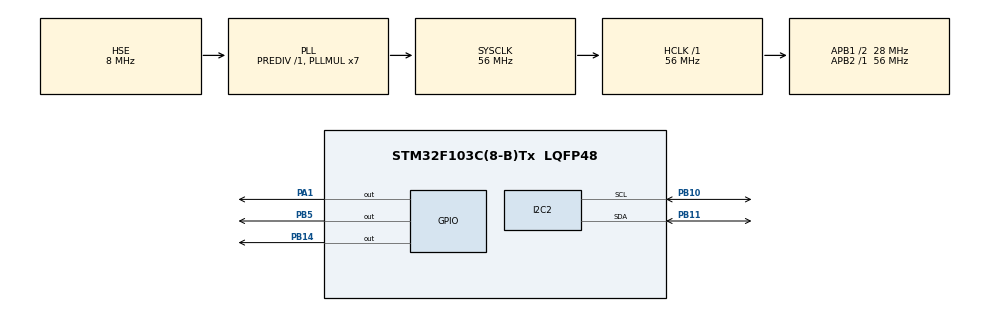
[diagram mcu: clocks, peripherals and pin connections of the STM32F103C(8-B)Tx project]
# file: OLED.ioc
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Mcu.Family=STM32F1
Mcu.Name=STM32F103C(8-B)Tx
Mcu.Package=LQFP48
NVIC.PriorityGroup=NVIC_PRIORITYGROUP_4
PA1.GPIO_PuPd=GPIO_PULLUP
PA1.GPIO_Speed=GPIO_SPEED_FREQ_HIGH
PA1.PinState=GPIO_PIN_SET
PA1.Signal=GPIO_Output
PA13.Mode=Serial_Wire
PA13.Signal=SYS_JTMS-SWDIO
PA14.Mode=Serial_Wire
PA14.Signal=SYS_JTCK-SWCLK
PB10.Mode=I2C
PB10.Signal=I2C2_SCL
PB11.Mode=I2C
PB11.Signal=I2C2_SDA
PB14.GPIO_PuPd=GPIO_PULLUP
PB14.GPIO_Speed=GPIO_SPEED_FREQ_HIGH
PB14.PinState=GPIO_PIN_SET
PB14.Signal=GPIO_Output
PB5.GPIO_PuPd=GPIO_PULLUP
PB5.GPIO_Speed=GPIO_SPEED_FREQ_HIGH
PB5.PinState=GPIO_PIN_SET
PB5.Signal=GPIO_Output
PD0-OSC_IN.Mode=HSE-External-Oscillator
PD0-OSC_IN.Signal=RCC_OSC_IN
PD1-OSC_OUT.Mode=HSE-External-Oscillator
PD1-OSC_OUT.Signal=RCC_OSC_OUT
ProjectManager.HeapSize=0x200
ProjectManager.StackSize=0x400
ProjectManager.TargetToolchain=MDK-ARM V5.27
RCC.AHBFreq_Value=56000000
RCC.APB1CLKDivider=RCC_HCLK_DIV2
RCC.APB1Freq_Value=28000000
RCC.APB1TimFreq_Value=56000000
RCC.APB2Freq_Value=56000000
RCC.APB2TimFreq_Value=56000000
RCC.HCLKFreq_Value=56000000
RCC.PLLMUL=RCC_PLL_MUL7
RCC.PLLSourceVirtual=RCC_PLLSOURCE_HSE
RCC.SYSCLKFreq_VALUE=56000000
RCC.SYSCLKSource=RCC_SYSCLKSOURCE_PLLCLK
RCC.USBFreq_Value=56000000
board=custom

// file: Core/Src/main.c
/* USER CODE BEGIN Header */
/**
  ******************************************************************************
  * @file           : main.c
  * @brief          : Main program body
  ******************************************************************************
  * @attention
  *
  * <h2><center>&copy; Copyright (c) 2022 STMicroelectronics.
  * All rights reserved.</center></h2>
  *
  * This software component is licensed by ST under BSD 3-Clause license,
  * the "License"; You may not use this file except in compliance with the
  * License. You may obtain a copy of the License at:
  *                        opensource.org/licenses/BSD-3-Clause
  *
  ******************************************************************************
  */
/* USER CODE END Header */
#include "main.h"
#include "i2c.h"
#include "gpio.h"

/* USER CODE BEGIN Includes */

//void power_pin_init(void)
//{
//	GPIO_InitTypeDef  GPIO_InitStructure;
//	RCC_APB2PeriphClockCmd(RCC_APB2Periph_GPIOB, ENABLE);
//	GPIO_InitStructure.GPIO_Pin = GPIO_Pin_12;//	 PB12 POWER控制端口
// 	GPIO_InitStructure.GPIO_Mode =GPIO_Mode_Out_PP; 		 //推挽输出
//	GPIO_InitStructure.GPIO_Speed = GPIO_Speed_2MHz;//速度
// 	GPIO_Init(GPIOB, &GPIO_InitStructure);
//	GPIO_SetBits(GPIOB,GPIO_Pin_12);
//}
/* USER CODE END Includes */

void SystemClock_Config(void);

int main(void)
{

  /* MCU Configuration--------------------------------------------------------*/

  /* Reset of all peripherals, Initializes the Flash interface and the Systick. */
  HAL_Init();

  /* Configure the system clock */
  SystemClock_Config();

  /* Initialize all configured peripherals */
  MX_GPIO_Init();
  MX_I2C2_Init();
  c_control_init;
  /* Infinite loop */
  while (1)
  {
   c_control_loop;
  }
}

void SystemClock_Config(void)
{
  RCC_OscInitTypeDef RCC_OscInitStruct = {0};
  RCC_ClkInitTypeDef RCC_ClkInitStruct = {0};

  /** Initializes the RCC Oscillators according to the specified parameters
  * in the RCC_OscInitTypeDef structure.
  */
  RCC_OscInitStruct.OscillatorType = RCC_OSCILLATORTYPE_HSE;
  RCC_OscInitStruct.HSEState = RCC_HSE_ON;
  RCC_OscInitStruct.HSEPredivValue = RCC_HSE_PREDIV_DIV1;
  RCC_OscInitStruct.HSIState = RCC_HSI_ON;
  RCC_OscInitStruct.PLL.PLLState = RCC_PLL_ON;
  RCC_OscInitStruct.PLL.PLLSource = RCC_PLLSOURCE_HSE;
  RCC_OscInitStruct.PLL.PLLMUL = RCC_PLL_MUL7;
  if (HAL_RCC_OscConfig(&RCC_OscInitStruct) != HAL_OK)
  {
    Error_Handler();
  }
  /** Initializes the CPU, AHB and APB buses clocks
  */
  RCC_ClkInitStruct.ClockType = RCC_CLOCKTYPE_HCLK|RCC_CLOCKTYPE_SYSCLK
                              |RCC_CLOCKTYPE_PCLK1|RCC_CLOCKTYPE_PCLK2;
  RCC_ClkInitStruct.SYSCLKSource = RCC_SYSCLKSOURCE_PLLCLK;
  RCC_ClkInitStruct.AHBCLKDivider = RCC_SYSCLK_DIV1;
  RCC_ClkInitStruct.APB1CLKDivider = RCC_HCLK_DIV2;
  RCC_ClkInitStruct.APB2CLKDivider = RCC_HCLK_DIV1;

  if (HAL_RCC_ClockConfig(&RCC_ClkInitStruct, FLASH_LATENCY_2) != HAL_OK)
  {
    Error_Handler();
  }
}

void Error_Handler(void)
{
  __disable_irq();
  while (1)
  {
  }
}

/************************ (C) COPYRIGHT STMicroelectronics *****END OF FILE****/
